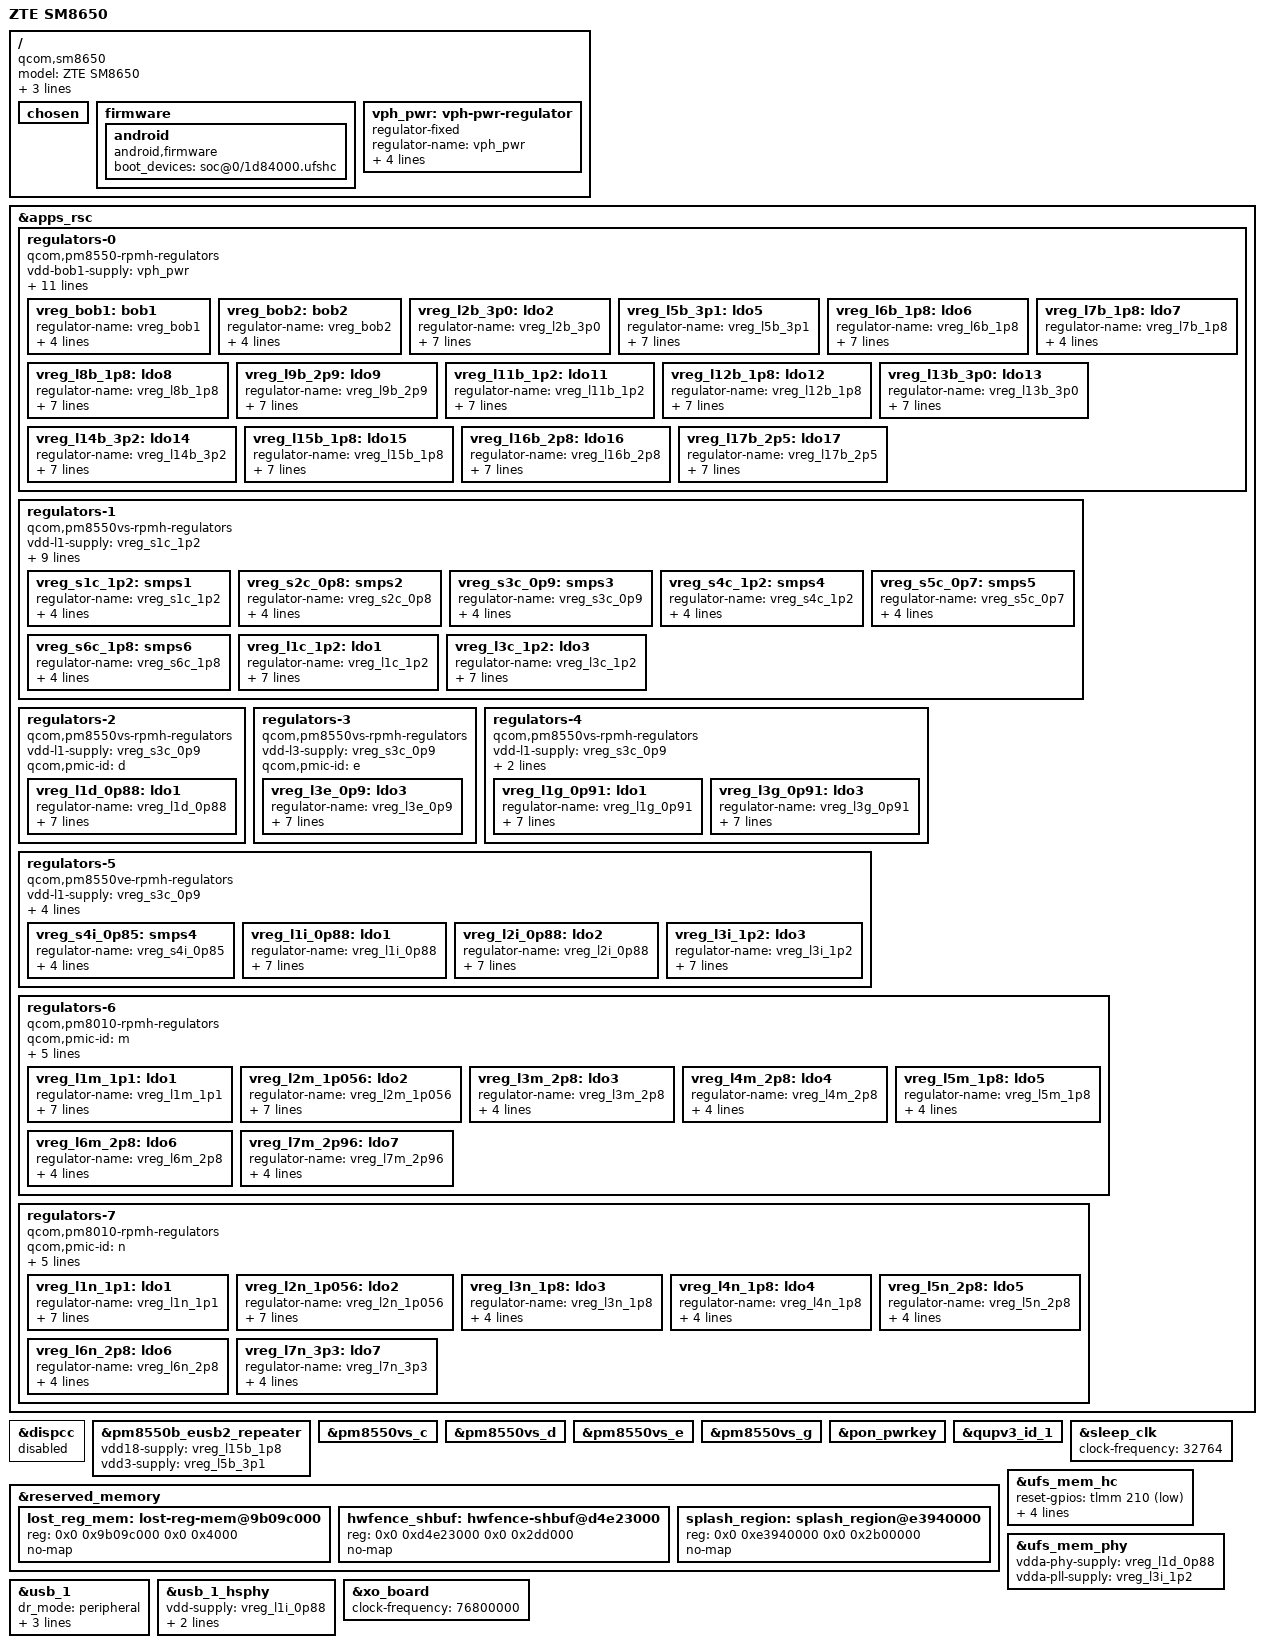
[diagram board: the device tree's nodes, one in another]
// SPDX-License-Identifier: BSD-3-Clause

/dts-v1/;

#include <dt-bindings/arm/qcom,ids.h>
#include <dt-bindings/regulator/qcom,rpmh-regulator.h>
#include "sm8650.dtsi"
#include "pm8010.dtsi"
#include "pm8550.dtsi"
#include "pm8550b.dtsi"
#define PMK8550VE_SID 8
#include "pm8550ve.dtsi"
#include "pm8550vs.dtsi"
#include "pmk8550.dtsi"
#include "pmr735d_a.dtsi"

/delete-node/ &hwfence_shbuf;

/ {
	model = "ZTE SM8650";
	compatible = "qcom,sm8650";

	qcom,msm-id = <QCOM_ID_SM8650 0x20000>, <577 0x20000>;
	qcom,board-id = <0 0>;

	chosen: chosen {
		#address-cells = <2>;
		#size-cells = <2>;
		ranges;
	};

	firmware {
		android {
			compatible = "android,firmware";
			boot_devices = "soc@0/1d84000.ufshc";
		};
	};

	vph_pwr: vph-pwr-regulator {
		compatible = "regulator-fixed";

		regulator-name = "vph_pwr";
		regulator-min-microvolt = <3700000>;
		regulator-max-microvolt = <3700000>;

		regulator-always-on;
		regulator-boot-on;
	};
};

&apps_rsc {
	regulators-0 {
		compatible = "qcom,pm8550-rpmh-regulators";

		vdd-bob1-supply = <&vph_pwr>;
		vdd-bob2-supply = <&vph_pwr>;
		vdd-l2-l13-l14-supply = <&vreg_bob1>;
		vdd-l3-supply = <&vreg_s1c_1p2>;
		vdd-l5-l16-supply = <&vreg_bob1>;
		vdd-l6-l7-supply = <&vreg_bob1>;
		vdd-l8-l9-supply = <&vreg_bob1>;
		vdd-l11-supply = <&vreg_s1c_1p2>;
		vdd-l12-supply = <&vreg_s6c_1p8>;
		vdd-l15-supply = <&vreg_s6c_1p8>;
		vdd-l17-supply = <&vreg_bob2>;

		qcom,pmic-id = "b";

		vreg_bob1: bob1 {
			regulator-name = "vreg_bob1";
			regulator-min-microvolt = <3296000>;
			regulator-max-microvolt = <3960000>;
			regulator-initial-mode = <RPMH_REGULATOR_MODE_HPM>;
		};

		vreg_bob2: bob2 {
			regulator-name = "vreg_bob2";
			regulator-min-microvolt = <2720000>;
			regulator-max-microvolt = <3008000>;
			regulator-initial-mode = <RPMH_REGULATOR_MODE_HPM>;
		};

		vreg_l2b_3p0: ldo2 {
			regulator-name = "vreg_l2b_3p0";
			regulator-min-microvolt = <3008000>;
			regulator-max-microvolt = <3008000>;
			regulator-initial-mode = <RPMH_REGULATOR_MODE_HPM>;
			regulator-allow-set-load;
			regulator-allowed-modes = <RPMH_REGULATOR_MODE_LPM
						   RPMH_REGULATOR_MODE_HPM>;
		};

		vreg_l5b_3p1: ldo5 {
			regulator-name = "vreg_l5b_3p1";
			regulator-min-microvolt = <3104000>;
			regulator-max-microvolt = <3104000>;
			regulator-initial-mode = <RPMH_REGULATOR_MODE_HPM>;
			regulator-allow-set-load;
			regulator-allowed-modes = <RPMH_REGULATOR_MODE_LPM
						   RPMH_REGULATOR_MODE_HPM>;
		};

		vreg_l6b_1p8: ldo6 {
			regulator-name = "vreg_l6b_1p8";
			regulator-min-microvolt = <1800000>;
			regulator-max-microvolt = <3008000>;
			regulator-initial-mode = <RPMH_REGULATOR_MODE_HPM>;
			regulator-allow-set-load;
			regulator-allowed-modes = <RPMH_REGULATOR_MODE_LPM
						   RPMH_REGULATOR_MODE_HPM>;
		};

		vreg_l7b_1p8: ldo7 {
			regulator-name = "vreg_l7b_1p8";
			regulator-min-microvolt = <1800000>;
			regulator-max-microvolt = <3008000>;
			regulator-initial-mode = <RPMH_REGULATOR_MODE_HPM>;
		};

		vreg_l8b_1p8: ldo8 {
			regulator-name = "vreg_l8b_1p8";
			regulator-min-microvolt = <1800000>;
			regulator-max-microvolt = <3008000>;
			regulator-initial-mode = <RPMH_REGULATOR_MODE_HPM>;
			regulator-allow-set-load;
			regulator-allowed-modes = <RPMH_REGULATOR_MODE_LPM
						   RPMH_REGULATOR_MODE_HPM>;
		};

		vreg_l9b_2p9: ldo9 {
			regulator-name = "vreg_l9b_2p9";
			regulator-min-microvolt = <2960000>;
			regulator-max-microvolt = <3008000>;
			regulator-initial-mode = <RPMH_REGULATOR_MODE_HPM>;
			regulator-allow-set-load;
			regulator-allowed-modes = <RPMH_REGULATOR_MODE_LPM
						   RPMH_REGULATOR_MODE_HPM>;
		};

		vreg_l11b_1p2: ldo11 {
			regulator-name = "vreg_l11b_1p2";
			regulator-min-microvolt = <1200000>;
			regulator-max-microvolt = <1200000>;
			regulator-initial-mode = <RPMH_REGULATOR_MODE_HPM>;
			regulator-allow-set-load;
			regulator-allowed-modes = <RPMH_REGULATOR_MODE_LPM
						   RPMH_REGULATOR_MODE_HPM>;
		};

		vreg_l12b_1p8: ldo12 {
			regulator-name = "vreg_l12b_1p8";
			regulator-min-microvolt = <1800000>;
			regulator-max-microvolt = <1800000>;
			regulator-initial-mode = <RPMH_REGULATOR_MODE_HPM>;
			regulator-allow-set-load;
			regulator-allowed-modes = <RPMH_REGULATOR_MODE_LPM
						   RPMH_REGULATOR_MODE_HPM>;
		};

		vreg_l13b_3p0: ldo13 {
			regulator-name = "vreg_l13b_3p0";
			regulator-min-microvolt = <3000000>;
			regulator-max-microvolt = <3000000>;
			regulator-initial-mode = <RPMH_REGULATOR_MODE_HPM>;
			regulator-allow-set-load;
			regulator-allowed-modes = <RPMH_REGULATOR_MODE_LPM
						   RPMH_REGULATOR_MODE_HPM>;
		};

		vreg_l14b_3p2: ldo14 {
			regulator-name = "vreg_l14b_3p2";
			regulator-min-microvolt = <3200000>;
			regulator-max-microvolt = <3200000>;
			regulator-initial-mode = <RPMH_REGULATOR_MODE_HPM>;
			regulator-allow-set-load;
			regulator-allowed-modes = <RPMH_REGULATOR_MODE_LPM
						   RPMH_REGULATOR_MODE_HPM>;
		};

		vreg_l15b_1p8: ldo15 {
			regulator-name = "vreg_l15b_1p8";
			regulator-min-microvolt = <1800000>;
			regulator-max-microvolt = <1800000>;
			regulator-initial-mode = <RPMH_REGULATOR_MODE_HPM>;
			regulator-allow-set-load;
			regulator-allowed-modes = <RPMH_REGULATOR_MODE_LPM
						   RPMH_REGULATOR_MODE_HPM>;
		};

		vreg_l16b_2p8: ldo16 {
			regulator-name = "vreg_l16b_2p8";
			regulator-min-microvolt = <2800000>;
			regulator-max-microvolt = <2800000>;
			regulator-initial-mode = <RPMH_REGULATOR_MODE_HPM>;
			regulator-allow-set-load;
			regulator-allowed-modes = <RPMH_REGULATOR_MODE_LPM
						   RPMH_REGULATOR_MODE_HPM>;
		};

		vreg_l17b_2p5: ldo17 {
			regulator-name = "vreg_l17b_2p5";
			regulator-min-microvolt = <2504000>;
			regulator-max-microvolt = <2504000>;
			regulator-initial-mode = <RPMH_REGULATOR_MODE_HPM>;
			regulator-allow-set-load;
			regulator-allowed-modes = <RPMH_REGULATOR_MODE_LPM
						   RPMH_REGULATOR_MODE_HPM>;
		};
	};

	regulators-1 {
		compatible = "qcom,pm8550vs-rpmh-regulators";

		vdd-l1-supply = <&vreg_s1c_1p2>;
		vdd-l2-supply = <&vreg_s1c_1p2>;
		vdd-l3-supply = <&vreg_s1c_1p2>;
		vdd-s1-supply = <&vph_pwr>;
		vdd-s2-supply = <&vph_pwr>;
		vdd-s3-supply = <&vph_pwr>;
		vdd-s4-supply = <&vph_pwr>;
		vdd-s5-supply = <&vph_pwr>;
		vdd-s6-supply = <&vph_pwr>;

		qcom,pmic-id = "c";

		vreg_s1c_1p2: smps1 {
			regulator-name = "vreg_s1c_1p2";
			regulator-min-microvolt = <1256000>;
			regulator-max-microvolt = <1348000>;
			regulator-initial-mode = <RPMH_REGULATOR_MODE_HPM>;
		};

		vreg_s2c_0p8: smps2 {
			regulator-name = "vreg_s2c_0p8";
			regulator-min-microvolt = <852000>;
			regulator-max-microvolt = <1036000>;
			regulator-initial-mode = <RPMH_REGULATOR_MODE_HPM>;
		};

		vreg_s3c_0p9: smps3 {
			regulator-name = "vreg_s3c_0p9";
			regulator-min-microvolt = <976000>;
			regulator-max-microvolt = <1064000>;
			regulator-initial-mode = <RPMH_REGULATOR_MODE_HPM>;
		};

		vreg_s4c_1p2: smps4 {
			regulator-name = "vreg_s4c_1p2";
			regulator-min-microvolt = <1224000>;
			regulator-max-microvolt = <1280000>;
			regulator-initial-mode = <RPMH_REGULATOR_MODE_HPM>;
		};

		vreg_s5c_0p7: smps5 {
			regulator-name = "vreg_s5c_0p7";
			regulator-min-microvolt = <752000>;
			regulator-max-microvolt = <900000>;
			regulator-initial-mode = <RPMH_REGULATOR_MODE_HPM>;
		};

		vreg_s6c_1p8: smps6 {
			regulator-name = "vreg_s6c_1p8";
			regulator-min-microvolt = <1856000>;
			regulator-max-microvolt = <2000000>;
			regulator-initial-mode = <RPMH_REGULATOR_MODE_HPM>;
		};

		vreg_l1c_1p2: ldo1 {
			regulator-name = "vreg_l1c_1p2";
			regulator-min-microvolt = <1200000>;
			regulator-max-microvolt = <1200000>;
			regulator-initial-mode = <RPMH_REGULATOR_MODE_HPM>;
			regulator-allow-set-load;
			regulator-allowed-modes = <RPMH_REGULATOR_MODE_LPM
						   RPMH_REGULATOR_MODE_HPM>;
		};

		vreg_l3c_1p2: ldo3 {
			regulator-name = "vreg_l3c_1p2";
			regulator-min-microvolt = <1200000>;
			regulator-max-microvolt = <1200000>;
			regulator-initial-mode = <RPMH_REGULATOR_MODE_HPM>;
			regulator-allow-set-load;
			regulator-allowed-modes = <RPMH_REGULATOR_MODE_LPM
						   RPMH_REGULATOR_MODE_HPM>;
		};
	};

	regulators-2 {
		compatible = "qcom,pm8550vs-rpmh-regulators";

		vdd-l1-supply = <&vreg_s3c_0p9>;

		qcom,pmic-id = "d";

		vreg_l1d_0p88: ldo1 {
			regulator-name = "vreg_l1d_0p88";
			regulator-min-microvolt = <912000>;
			regulator-max-microvolt = <920000>;
			regulator-initial-mode = <RPMH_REGULATOR_MODE_HPM>;
			regulator-allow-set-load;
			regulator-allowed-modes = <RPMH_REGULATOR_MODE_LPM
						   RPMH_REGULATOR_MODE_HPM>;
		};
	};

	regulators-3 {
		compatible = "qcom,pm8550vs-rpmh-regulators";

		vdd-l3-supply = <&vreg_s3c_0p9>;

		qcom,pmic-id = "e";

		vreg_l3e_0p9: ldo3 {
			regulator-name = "vreg_l3e_0p9";
			regulator-min-microvolt = <880000>;
			regulator-max-microvolt = <920000>;
			regulator-initial-mode = <RPMH_REGULATOR_MODE_HPM>;
			regulator-allow-set-load;
			regulator-allowed-modes = <RPMH_REGULATOR_MODE_LPM
						   RPMH_REGULATOR_MODE_HPM>;
		};
	};

	regulators-4 {
		compatible = "qcom,pm8550vs-rpmh-regulators";

		vdd-l1-supply = <&vreg_s3c_0p9>;
		vdd-l3-supply = <&vreg_s3c_0p9>;

		qcom,pmic-id = "g";

		vreg_l1g_0p91: ldo1 {
			regulator-name = "vreg_l1g_0p91";
			regulator-min-microvolt = <912000>;
			regulator-max-microvolt = <920000>;
			regulator-initial-mode = <RPMH_REGULATOR_MODE_HPM>;
			regulator-allow-set-load;
			regulator-allowed-modes = <RPMH_REGULATOR_MODE_LPM
						   RPMH_REGULATOR_MODE_HPM>;
		};

		vreg_l3g_0p91: ldo3 {
			regulator-name = "vreg_l3g_0p91";
			regulator-min-microvolt = <880000>;
			regulator-max-microvolt = <912000>;
			regulator-initial-mode = <RPMH_REGULATOR_MODE_HPM>;
			regulator-allow-set-load;
			regulator-allowed-modes = <RPMH_REGULATOR_MODE_LPM
						   RPMH_REGULATOR_MODE_HPM>;
		};
	};

	regulators-5 {
		compatible = "qcom,pm8550ve-rpmh-regulators";

		vdd-l1-supply = <&vreg_s3c_0p9>;
		vdd-l2-supply = <&vreg_s3c_0p9>;
		vdd-l3-supply = <&vreg_s1c_1p2>;
		vdd-s4-supply = <&vph_pwr>;

		qcom,pmic-id = "i";

		vreg_s4i_0p85: smps4 {
			regulator-name = "vreg_s4i_0p85";
			regulator-min-microvolt = <852000>;
			regulator-max-microvolt = <1004000>;
			regulator-initial-mode = <RPMH_REGULATOR_MODE_HPM>;
		};

		vreg_l1i_0p88: ldo1 {
			regulator-name = "vreg_l1i_0p88";
			regulator-min-microvolt = <880000>;
			regulator-max-microvolt = <912000>;
			regulator-initial-mode = <RPMH_REGULATOR_MODE_HPM>;
			regulator-allow-set-load;
			regulator-allowed-modes = <RPMH_REGULATOR_MODE_LPM
						   RPMH_REGULATOR_MODE_HPM>;
		};

		vreg_l2i_0p88: ldo2 {
			regulator-name = "vreg_l2i_0p88";
			regulator-min-microvolt = <880000>;
			regulator-max-microvolt = <912000>;
			regulator-initial-mode = <RPMH_REGULATOR_MODE_HPM>;
			regulator-allow-set-load;
			regulator-allowed-modes = <RPMH_REGULATOR_MODE_LPM
						   RPMH_REGULATOR_MODE_HPM>;
		};

		vreg_l3i_1p2: ldo3 {
			regulator-name = "vreg_l3i_1p2";
			regulator-min-microvolt = <1200000>;
			regulator-max-microvolt = <1200000>;
			regulator-initial-mode = <RPMH_REGULATOR_MODE_HPM>;
			regulator-allow-set-load;
			regulator-allowed-modes = <RPMH_REGULATOR_MODE_LPM
						   RPMH_REGULATOR_MODE_HPM>;
		};
	};

	regulators-6 {
		compatible = "qcom,pm8010-rpmh-regulators";
		qcom,pmic-id = "m";

		vdd-l1-l2-supply = <&vreg_s1c_1p2>;
		vdd-l3-l4-supply = <&vreg_bob2>;
		vdd-l5-supply = <&vreg_s6c_1p8>;
		vdd-l6-supply = <&vreg_bob1>;
		vdd-l7-supply = <&vreg_bob1>;

		vreg_l1m_1p1: ldo1 {
			regulator-name = "vreg_l1m_1p1";
			regulator-min-microvolt = <1104000>;
			regulator-max-microvolt = <1104000>;
			regulator-initial-mode = <RPMH_REGULATOR_MODE_HPM>;
			regulator-allow-set-load;
			regulator-allowed-modes = <RPMH_REGULATOR_MODE_LPM
						   RPMH_REGULATOR_MODE_HPM>;
		};

		vreg_l2m_1p056: ldo2 {
			regulator-name = "vreg_l2m_1p056";
			regulator-min-microvolt = <1056000>;
			regulator-max-microvolt = <1056000>;
			regulator-initial-mode = <RPMH_REGULATOR_MODE_HPM>;
			regulator-allow-set-load;
			regulator-allowed-modes = <RPMH_REGULATOR_MODE_LPM
						   RPMH_REGULATOR_MODE_HPM>;
		};

		vreg_l3m_2p8: ldo3 {
			regulator-name = "vreg_l3m_2p8";
			regulator-min-microvolt = <2800000>;
			regulator-max-microvolt = <2800000>;
			regulator-initial-mode = <RPMH_REGULATOR_MODE_HPM>;
		};

		vreg_l4m_2p8: ldo4 {
			regulator-name = "vreg_l4m_2p8";
			regulator-min-microvolt = <2800000>;
			regulator-max-microvolt = <2800000>;
			regulator-initial-mode = <RPMH_REGULATOR_MODE_HPM>;
		};

		vreg_l5m_1p8: ldo5 {
			regulator-name = "vreg_l5m_1p8";
			regulator-min-microvolt = <1800000>;
			regulator-max-microvolt = <1800000>;
			regulator-initial-mode = <RPMH_REGULATOR_MODE_HPM>;
		};

		vreg_l6m_2p8: ldo6 {
			regulator-name = "vreg_l6m_2p8";
			regulator-min-microvolt = <2800000>;
			regulator-max-microvolt = <2800000>;
			regulator-initial-mode = <RPMH_REGULATOR_MODE_HPM>;
		};

		vreg_l7m_2p96: ldo7 {
			regulator-name = "vreg_l7m_2p96";
			regulator-min-microvolt = <2960000>;
			regulator-max-microvolt = <2960000>;
			regulator-initial-mode = <RPMH_REGULATOR_MODE_HPM>;
		};
	};

	regulators-7 {
		compatible = "qcom,pm8010-rpmh-regulators";
		qcom,pmic-id = "n";

		vdd-l1-l2-supply = <&vreg_s1c_1p2>;
		vdd-l3-l4-supply = <&vreg_s6c_1p8>;
		vdd-l5-supply = <&vreg_bob2>;
		vdd-l6-supply = <&vreg_bob2>;
		vdd-l7-supply = <&vreg_bob1>;

		vreg_l1n_1p1: ldo1 {
			regulator-name = "vreg_l1n_1p1";
			regulator-min-microvolt = <1104000>;
			regulator-max-microvolt = <1104000>;
			regulator-initial-mode = <RPMH_REGULATOR_MODE_HPM>;
			regulator-allow-set-load;
			regulator-allowed-modes = <RPMH_REGULATOR_MODE_LPM
						   RPMH_REGULATOR_MODE_HPM>;
		};

		vreg_l2n_1p056: ldo2 {
			regulator-name = "vreg_l2n_1p056";
			regulator-min-microvolt = <1056000>;
			regulator-max-microvolt = <1056000>;
			regulator-initial-mode = <RPMH_REGULATOR_MODE_HPM>;
			regulator-allow-set-load;
			regulator-allowed-modes = <RPMH_REGULATOR_MODE_LPM
						   RPMH_REGULATOR_MODE_HPM>;
		};

		vreg_l3n_1p8: ldo3 {
			regulator-name = "vreg_l3n_1p8";
			regulator-min-microvolt = <1800000>;
			regulator-max-microvolt = <1800000>;
			regulator-initial-mode = <RPMH_REGULATOR_MODE_HPM>;
		};

		vreg_l4n_1p8: ldo4 {
			regulator-name = "vreg_l4n_1p8";
			regulator-min-microvolt = <1800000>;
			regulator-max-microvolt = <1800000>;
			regulator-initial-mode = <RPMH_REGULATOR_MODE_HPM>;
		};

		vreg_l5n_2p8: ldo5 {
			regulator-name = "vreg_l5n_2p8";
			regulator-min-microvolt = <2800000>;
			regulator-max-microvolt = <2800000>;
			regulator-initial-mode = <RPMH_REGULATOR_MODE_HPM>;
		};

		vreg_l6n_2p8: ldo6 {
			regulator-name = "vreg_l6n_2p8";
			regulator-min-microvolt = <2800000>;
			regulator-max-microvolt = <2800000>;
			regulator-initial-mode = <RPMH_REGULATOR_MODE_HPM>;
		};

		vreg_l7n_3p3: ldo7 {
			regulator-name = "vreg_l7n_3p3";
			regulator-min-microvolt = <3304000>;
			regulator-max-microvolt = <3304000>;
			regulator-initial-mode = <RPMH_REGULATOR_MODE_HPM>;
		};
	};
};

&dispcc {
	/* Disable for now so simple-framebuffer continues working */
	status = "disabled";
};

&pm8550b_eusb2_repeater {
	vdd18-supply = <&vreg_l15b_1p8>;
	vdd3-supply = <&vreg_l5b_3p1>;
};

&pm8550vs_c {
	status = "okay";
};

&pm8550vs_d {
	status = "okay";
};

&pm8550vs_e {
	status = "okay";
};

&pm8550vs_g {
	status = "okay";
};

&pon_pwrkey {
	status = "okay";
};

&qupv3_id_1 {
	status = "okay";
};

&reserved_memory {
	lost_reg_mem: lost-reg-mem@9b09c000 {
		reg = <0x0 0x9b09c000 0x0 0x4000>;
		no-map;
	};

	hwfence_shbuf: hwfence-shbuf@d4e23000 {
		reg = <0x0 0xd4e23000 0x0 0x2dd000>;
		no-map;
	};

	/*
	 * ABL is powering down display and controller if this node is
	 * not named exactly "splash_region".
	 */
	splash_region: splash_region@e3940000 {
		reg = <0x0 0xe3940000 0x0 0x2b00000>;
		no-map;
	};
};

&sleep_clk {
	clock-frequency = <32764>;
};

&ufs_mem_hc {
	reset-gpios = <&tlmm 210 GPIO_ACTIVE_LOW>;

	vcc-supply = <&vreg_l17b_2p5>;
	vcc-max-microamp = <1300000>;
	vccq-supply = <&vreg_l1c_1p2>;
	vccq-max-microamp = <1200000>;

	status = "okay";
};

&ufs_mem_phy {
	vdda-phy-supply = <&vreg_l1d_0p88>;
	vdda-pll-supply = <&vreg_l3i_1p2>;

	status = "okay";
};

&usb_1 {
	dr_mode = "peripheral";
	maximum-speed = "high-speed";
	phys = <&usb_1_hsphy>;
	phy-names = "usb2-phy";

	qcom,select-utmi-as-pipe-clk;

	status = "okay";
};

&usb_1_hsphy {
	vdd-supply = <&vreg_l1i_0p88>;
	vdda12-supply = <&vreg_l3i_1p2>;

	phys = <&pm8550b_eusb2_repeater>;

	status = "okay";
};

&xo_board {
	clock-frequency = <76800000>;
};
